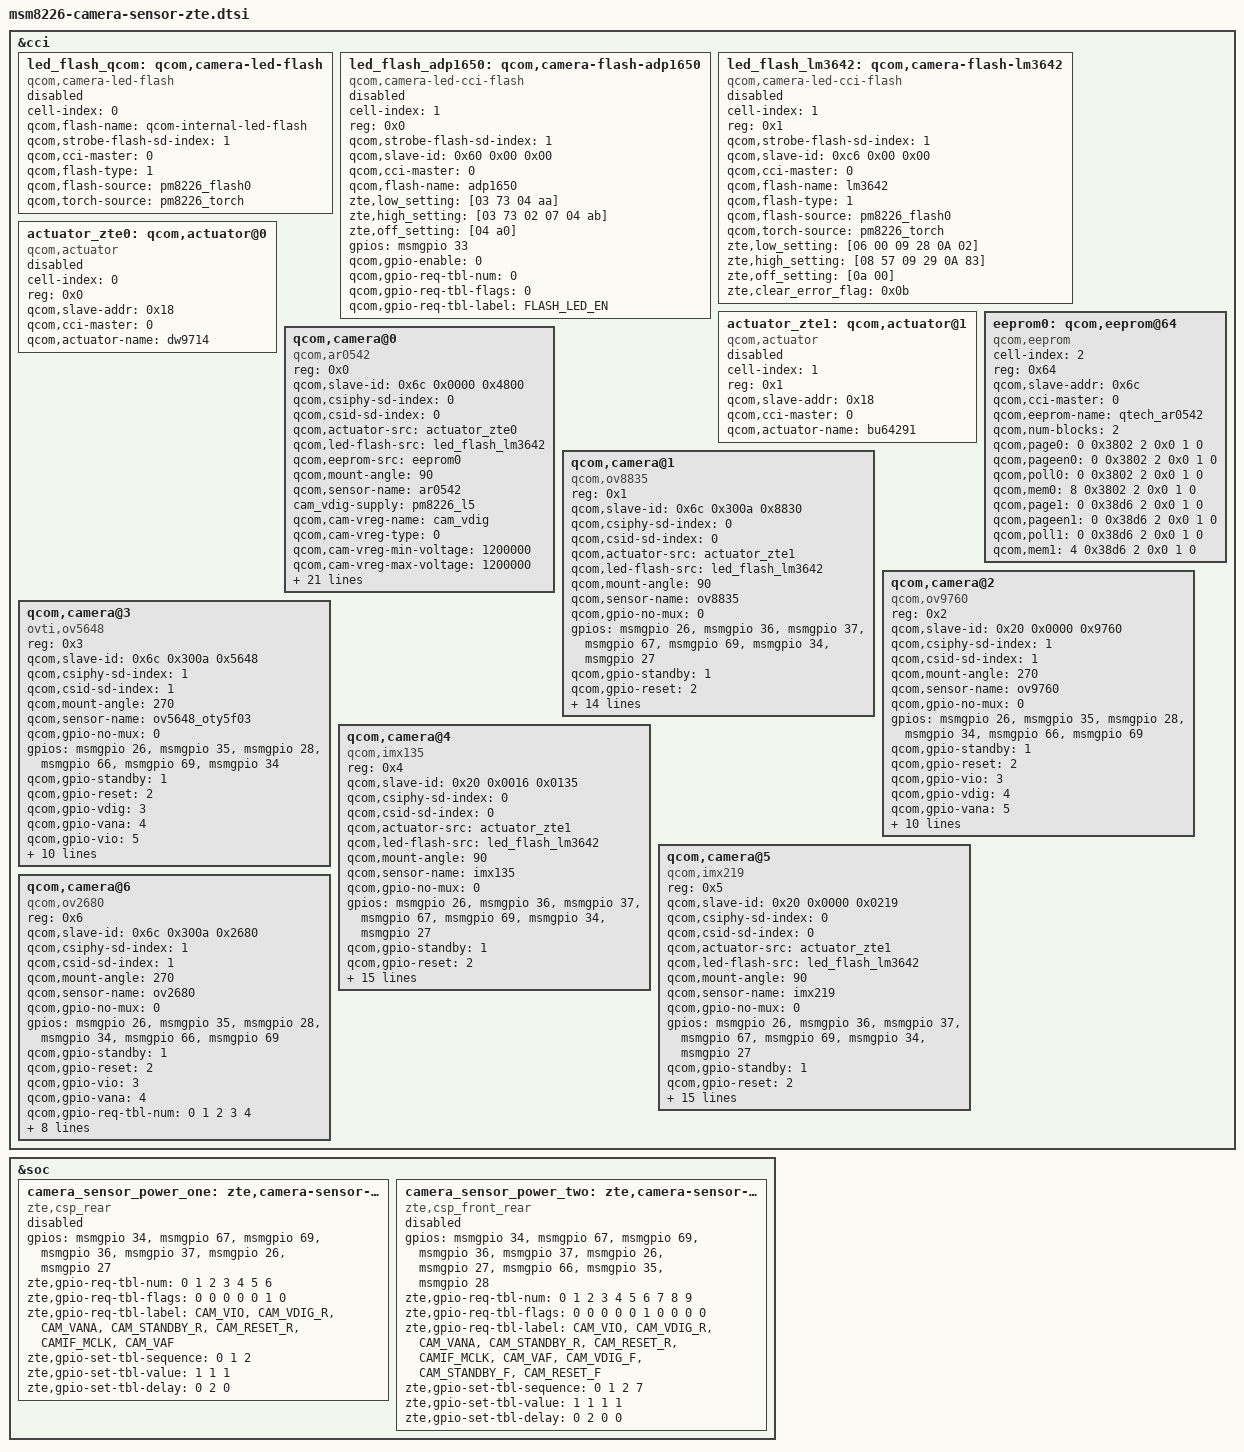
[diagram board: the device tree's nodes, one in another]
/*
 * Copyright (c) 2013, The Linux Foundation. All rights reserved.
 *
 * This program is free software; you can redistribute it and/or modify
 * it under the terms of the GNU General Public License version 2 and
 * only version 2 as published by the Free Software Foundation.
 *
 * This program is distributed in the hope that it will be useful,
 * but WITHOUT ANY WARRANTY; without even the implied warranty of
 * MERCHANTABILITY or FITNESS FOR A PARTICULAR PURPOSE.  See the
 * GNU General Public License for more details.
 */
	
&cci {

	/*
	 * Support for qcom internal flash
	 */
	led_flash_qcom: qcom,camera-led-flash {
		cell-index = <0>;
		qcom,flash-name = "qcom-internal-led-flash";
		qcom,strobe-flash-sd-index=<1>;
		compatible = "qcom,camera-led-flash";
		qcom,cci-master = <0>;
		qcom,flash-type = <1>;
		qcom,flash-source = <&pm8226_flash0>;
		qcom,torch-source = <&pm8226_torch>;
		status = "disabled";
	};

	
	/*
	 * Support for AD adp1650
	 */
	led_flash_adp1650:qcom,camera-flash-adp1650 {
		cell-index = <1>;
		reg = <0x0>;
		qcom,strobe-flash-sd-index=<1>;
		qcom,slave-id = <0x60 0x00 0x00>;
		compatible = "qcom,camera-led-cci-flash";
		qcom,cci-master = <0>;
		qcom,flash-name = "adp1650";
		zte,low_setting = [03  73  //torch current 100mA flash current 1000mA
					      04  aa];
		zte,high_setting = [03 73 //torch current 100mA flash current 1000mA
						02 07 //800ms
						04 ab];
		zte,off_setting = [04 a0];
		
		gpios = <&msmgpio 33 0>;
		qcom,gpio-enable = <0>;
		qcom,gpio-req-tbl-num = <0>;

		/* 0: output gpio, 1: input gpio */
		qcom,gpio-req-tbl-flags = <0>;

		qcom,gpio-req-tbl-label = "FLASH_LED_EN";

		status = "disabled";
	};

	/*
	 * Support for TI lm3642
	 */
	led_flash_lm3642: qcom,camera-flash-lm3642 {
		cell-index = <1>;
		reg = <0x1>;
		qcom,strobe-flash-sd-index=<1>;
		qcom,slave-id = <0xc6 0x00 0x00>;
		compatible = "qcom,camera-led-cci-flash";
		qcom,cci-master = <0>;
		qcom,flash-name = "lm3642";
		qcom,flash-type = <1>;
		qcom,flash-source = <&pm8226_flash0>;
		qcom,torch-source = <&pm8226_torch>;
		zte,low_setting = [06  00 // torch time, ramp-up time 16ms, ramp-down time 16ms
	 				      09  28   // current control, torch current 140.63mA, flash current 843.75mA
	 				      0A  02];  // enable register, torch mode, strobe pin disabled
		zte,high_setting = [08 57  // flash time, ramp time 1.024ms, time-out time 800ms
	 					09 29   // current control, torch current 140.63mA, flash current 937.5mA
	 					0A 83];  // enable register, flash mode, strobe pin disabled
		zte,off_setting = [0a 00];
		zte,clear_error_flag = <0x0b>;
		status = "disabled";
	};
	
	/*
	 * Support for Dongwoon dw9714
	 */
	actuator_zte0: qcom,actuator@0 {
		cell-index = <0>;
		reg = <0x0>;
		qcom,slave-addr = <0x18>;
		compatible = "qcom,actuator";
		qcom,cci-master = <0>;
		qcom,actuator-name = "dw9714";
		status = "disabled";
	};

	/*
	 * Support for Rohm bu64291
	 */
	actuator_zte1: qcom,actuator@1 {
		cell-index = <1>;
		reg = <0x1>;
		qcom,slave-addr = <0x18>;
		compatible = "qcom,actuator";
		qcom,cci-master = <0>;
		qcom,actuator-name = "bu64291";
		status = "disabled";
	};
	
	eeprom0: qcom,eeprom@64 {
	compatible = "qcom,eeprom";
	cell-index = <2>;
	reg = <0x64>;
	qcom,slave-addr = <0x6c>;
	qcom,cci-master = <0>;
	qcom,eeprom-name = "qtech_ar0542";
	qcom,num-blocks = <2>;

	qcom,page0   = <0 0x3802 2 0x0 1 0>;
	qcom,pageen0 = <0 0x3802 2 0x0 1 0>;
	qcom,poll0   = <0 0x3802 2 0x0 1 0>;
	qcom,mem0    = <8 0x3802 2 0x0 1 0>;

	qcom,page1   = <0 0x38d6 2 0x0 1 0>;
	qcom,pageen1 = <0 0x38d6 2 0x0 1 0>;
	qcom,poll1  = <0 0x38d6 2 0x0 1 0>;
	qcom,mem1    = <4 0x38d6 2 0x0 1 0>;
	};
	
	qcom,camera@0 {
		compatible = "qcom,ar0542";
		reg = <0x0>;
		qcom,slave-id = <0x6c 0x0000 0x4800>;
		qcom,csiphy-sd-index = <0>;
		qcom,csid-sd-index = <0>;
		qcom,actuator-src = <&actuator_zte0>;
		qcom,led-flash-src = <&led_flash_lm3642>;
		qcom,eeprom-src = <&eeprom0>;
		qcom,mount-angle = <90>;
		qcom,sensor-name = "ar0542";
		cam_vdig-supply = <&pm8226_l5>;
		qcom,cam-vreg-name = "cam_vdig";
		qcom,cam-vreg-type = <0>;
		qcom,cam-vreg-min-voltage = <1200000>;
		qcom,cam-vreg-max-voltage = <1200000>;
		qcom,cam-vreg-op-mode = <200000>;
		qcom,gpio-no-mux = <0>;
		gpios = <&msmgpio 26 0>,
			<&msmgpio 36 0>,
			<&msmgpio 37 0>,
			<&msmgpio 67 0>,
			<&msmgpio 69 0>,
			<&msmgpio 34 0>,
			<&msmgpio 27 0>;
		qcom,gpio-standby = <1>;
		qcom,gpio-reset = <2>;
		qcom,gpio-vdig = <3>;
		qcom,gpio-vana = <4>;
		qcom,gpio-vio = <5>;
		qcom,gpio-vaf = <6>;
		qcom,gpio-req-tbl-num = <0 1 2 3 4 5 6>;
		qcom,gpio-req-tbl-flags = <1 0 0 0 0 0 0>;
		qcom,gpio-req-tbl-label = "CAMIF_MCLK",
			"CAM_STANDBY",
			"CAM_RESET1",
			"CAM_VDIG",
			"CAM_VANA",
			"CAM_VIO",
			"CAM_VAF";
		qcom,csi-lane-assign = <0x4320>;
		qcom,csi-lane-mask = <0x7>;
		qcom,sensor-position = <0>;
		qcom,sensor-mode = <1>;
		qcom,cci-master = <0>;
		status = "ok";
	};

	qcom,camera@1 {
		compatible = "qcom,ov8835";
		reg = <0x1>;
		qcom,slave-id = <0x6c 0x300a 0x8830>;
		qcom,csiphy-sd-index = <0>;
		qcom,csid-sd-index = <0>;
		qcom,actuator-src = <&actuator_zte1>;
		qcom,led-flash-src = <&led_flash_lm3642>;
		qcom,mount-angle = <90>;
		qcom,sensor-name = "ov8835";
		qcom,gpio-no-mux = <0>;
		gpios = <&msmgpio 26 0>,
			<&msmgpio 36 0>,
			<&msmgpio 37 0>,
			<&msmgpio 67 0>,
			<&msmgpio 69 0>,
			<&msmgpio 34 0>,
			<&msmgpio 27 0>;
		qcom,gpio-standby = <1>;
		qcom,gpio-reset = <2>;
		qcom,gpio-vdig = <3>;
		qcom,gpio-vana = <4>;
		qcom,gpio-vio = <5>;
		qcom,gpio-vaf = <6>;
		qcom,gpio-req-tbl-num = <0 1 2 3 4 5 6>;
		qcom,gpio-req-tbl-flags = <1 0 0 0 0 0 0>;
		qcom,gpio-req-tbl-label = "CAMIF_MCLK",
			"CAM_STANDBY",
			"CAM_RESET1",
			"CAM_VDIG",
			"CAM_VANA",
			"CAM_VIO",
			"CAM_VAF";
		qcom,csi-lane-assign = <0x4320>;
		qcom,csi-lane-mask = <0x1f>;
		qcom,sensor-position = <0>;
		qcom,sensor-mode = <1>;
		qcom,cci-master = <0>;
		status = "ok";
	};

	qcom,camera@2 {
		compatible = "qcom,ov9760";
		reg = <0x2>;
		qcom,slave-id = <0x20 0x0000 0x9760>;
		qcom,csiphy-sd-index = <1>;
		qcom,csid-sd-index = <1>;
		qcom,mount-angle = <270>;
		qcom,sensor-name = "ov9760";
		qcom,gpio-no-mux = <0>;
		gpios = <&msmgpio 26 0>,
			<&msmgpio 35 0>,
			<&msmgpio 28 0>,
			<&msmgpio 34 0>,
			<&msmgpio 66 0>,
			<&msmgpio 69 0>;
		qcom,gpio-standby = <1>;
		qcom,gpio-reset = <2>;
		qcom,gpio-vio = <3>;
		qcom,gpio-vdig = <4>;
		qcom,gpio-vana = <5>;
		qcom,gpio-req-tbl-num = <0 1 2 3 4 5>;
		qcom,gpio-req-tbl-flags = <1 0 0 0 0 0>;
		qcom,gpio-req-tbl-label = "CAMIF_MCLK",
			"CAM_STANDBY",
			"CAM_RESET",
			"CAM_VIO",
			"CAM_VDIG",
			"CAM_VANA";
		qcom,csi-lane-assign = <0x4320>;
		qcom,csi-lane-mask = <0x3>;
		qcom,sensor-position = <1>;
		qcom,sensor-mode = <1>;
		qcom,cci-master = <0>;
		status = "ok";
	};
	qcom,camera@3 {
		compatible = "ovti,ov5648";
		reg = <0x3>;
		qcom,slave-id = <0x6c 0x300a 0x5648>;
		qcom,csiphy-sd-index = <1>;
		qcom,csid-sd-index = <1>;
		qcom,mount-angle = <270>;
		qcom,sensor-name = "ov5648_oty5f03";
		qcom,gpio-no-mux = <0>;
		gpios = <&msmgpio 26 0>,
			<&msmgpio 35 0>,
			<&msmgpio 28 0>,
			<&msmgpio 66 0>,
			<&msmgpio 69 0>,
			<&msmgpio 34 0>;
		qcom,gpio-standby = <1>;
		qcom,gpio-reset = <2>;
		qcom,gpio-vdig = <3>;
		qcom,gpio-vana = <4>;
		qcom,gpio-vio = <5>;
		qcom,gpio-req-tbl-num = <0 1 2 3 4 5>;
		qcom,gpio-req-tbl-flags = <1 0 0 0 0 0>;
		qcom,gpio-req-tbl-label = "CAMIF_MCLK",
			"CAM_STANDBY",
			"CAM_RESET1",
			"CAM_VDIG",
			"CAM_VANA",
			"CAM_VIO";
		qcom,csi-lane-assign = <0x4320>;
		qcom,csi-lane-mask = <0x3>;
		qcom,sensor-position = <1>;
		qcom,sensor-mode = <1>;
		qcom,cci-master = <0>;
		status = "ok";
	};

   	 qcom,camera@4 {
		compatible = "qcom,imx135";
		reg = <0x4>;
		qcom,slave-id = <0x20 0x0016 0x0135>;
		qcom,csiphy-sd-index = <0>;
		qcom,csid-sd-index = <0>;
		qcom,actuator-src = <&actuator_zte1>;
		qcom,led-flash-src = <&led_flash_lm3642>;
		qcom,mount-angle = <90>;
		qcom,sensor-name = "imx135";
		qcom,gpio-no-mux = <0>;
		gpios = <&msmgpio 26 0>,
			<&msmgpio 36 0>,
			<&msmgpio 37 0>,
			<&msmgpio 67 0>,
			<&msmgpio 69 0>,
			<&msmgpio 34 0>,
			<&msmgpio 27 0>;
		qcom,gpio-standby = <1>;
		qcom,gpio-reset = <2>;
		qcom,gpio-vdig = <3>;
		qcom,gpio-vana = <4>;
		qcom,gpio-vio = <5>;
		qcom,gpio-vaf = <6>;
		qcom,gpio-req-tbl-num = <0 1 2 3 4 5 6>;
		qcom,gpio-req-tbl-flags = <1 0 0 0 0 0 0>;
		qcom,gpio-req-tbl-label = "CAMIF_MCLK",
			"CAM_STANDBY",
			"CAM_RESET1",
			"CAM_VDIG",
			"CAM_VANA",
			"CAM_VIO",
			"CAM_VAF";
		qcom,csi-lane-assign = <0x4320>;
		qcom,csi-lane-mask = <0x1f>;
		qcom,sensor-position = <0>;
		qcom,sensor-mode = <0>;
		qcom,sensor-type = <0>;
		qcom,cci-master = <0>;
		status = "ok";
	};

   	 qcom,camera@5 {
		compatible = "qcom,imx219";
		reg = <0x5>;
		qcom,slave-id = <0x20 0x0000 0x0219>;
		qcom,csiphy-sd-index = <0>;
		qcom,csid-sd-index = <0>;
		qcom,actuator-src = <&actuator_zte1>;
		qcom,led-flash-src = <&led_flash_lm3642>;
		qcom,mount-angle = <90>;
		qcom,sensor-name = "imx219";
		qcom,gpio-no-mux = <0>;
		gpios = <&msmgpio 26 0>,
			<&msmgpio 36 0>,
			<&msmgpio 37 0>,
			<&msmgpio 67 0>,
			<&msmgpio 69 0>,
			<&msmgpio 34 0>,
			<&msmgpio 27 0>;
		qcom,gpio-standby = <1>;
		qcom,gpio-reset = <2>;
		qcom,gpio-vdig = <3>;
		qcom,gpio-vana = <4>;
		qcom,gpio-vio = <5>;
		qcom,gpio-vaf = <6>;
		qcom,gpio-req-tbl-num = <0 1 2 3 4 5 6>;
		qcom,gpio-req-tbl-flags = <1 0 0 0 0 0 0>;
		qcom,gpio-req-tbl-label = "CAMIF_MCLK",
			"CAM_STANDBY",
			"CAM_RESET1",
			"CAM_VDIG",
			"CAM_VANA",
			"CAM_VIO",
			"CAM_VAF";
		qcom,csi-lane-assign = <0x4320>;
		qcom,csi-lane-mask = <0x1f>;
		qcom,sensor-position = <0>;
		qcom,sensor-mode = <0>;
		qcom,sensor-type = <0>;
		qcom,cci-master = <0>;
		status = "ok";
	};

	qcom,camera@6 {
		compatible = "qcom,ov2680";
		reg = <0x6>;
		qcom,slave-id = <0x6c 0x300a 0x2680>;
		qcom,csiphy-sd-index = <1>;
		qcom,csid-sd-index = <1>;
		qcom,mount-angle = <270>;
		qcom,sensor-name = "ov2680";
		qcom,gpio-no-mux = <0>;
		gpios = <&msmgpio 26 0>,
			<&msmgpio 35 0>,
			<&msmgpio 28 0>,
			<&msmgpio 34 0>,
			<&msmgpio 66 0>,
			<&msmgpio 69 0>;
		qcom,gpio-standby = <1>;
		qcom,gpio-reset = <2>;
		qcom,gpio-vio = <3>;
		qcom,gpio-vana = <4>;
		qcom,gpio-req-tbl-num = <0 1 2 3 4>;
		qcom,gpio-req-tbl-flags = <1 0 0 0 0>;
		qcom,gpio-req-tbl-label = "CAMIF_MCLK",
			"CAM_STANDBY",
			"CAM_RESET",
			"CAM_VIO",
			"CAM_VANA";
		qcom,csi-lane-assign = <0x4320>;
		qcom,csi-lane-mask = <0x3>;
		qcom,sensor-position = <1>;
		qcom,sensor-mode = <1>;
		qcom,cci-master = <0>;
		status = "ok";
	};	 

};
&soc {
	//there is only rear camera
	camera_sensor_power_one:zte,camera-sensor-power_one {
		compatible = "zte,csp_rear";
		gpios = 
			     <&msmgpio 34 0>,  //CAM_VIO            0
			     <&msmgpio 67 0>,  //CAM_VDIG_R       1
			     <&msmgpio 69 0>,  //CAM_VANA          2
			   
			     
			     <&msmgpio 36 0>,  //CAM_STANDBY_R  3
			     <&msmgpio 37 0>,  //CAM_RESET_R      4
			     
			     <&msmgpio 26 0>,  //CAMIF_MCLK        5
			     
			     <&msmgpio 27 0>; //CAM_VAF             6	
			     
		zte,gpio-req-tbl-num = <0 1 2 3 4 5 6>;
		zte,gpio-req-tbl-flags = <0 0 0 0 0 1 0>; // 0:output low  1: input  2:output hight
		zte,gpio-req-tbl-label = "CAM_VIO",
							   "CAM_VDIG_R",
							   "CAM_VANA",
							   
							   "CAM_STANDBY_R",
							   "CAM_RESET_R",	
							   
							   "CAMIF_MCLK",
							   
							   "CAM_VAF";
							   
		zte,gpio-set-tbl-sequence = <0 1 2>; //power up sequence
		zte,gpio-set-tbl-value = <1 1 1>;      //power up ,gpio output value
		zte,gpio-set-tbl-delay = <0 2 0>;      //power up ,the delay after gpio output
		status = "disabled";
	};

	//there is front and rear camera	
	camera_sensor_power_two:zte,camera-sensor-power_two {
		compatible = "zte,csp_front_rear";
		gpios = 
			     <&msmgpio 34 0>,  //CAM_VIO            0
			     <&msmgpio 67 0>,  //CAM_VDIG_R       1
			     <&msmgpio 69 0>,  //CAM_VANA          2			   
			     
			     <&msmgpio 36 0>,  //CAM_STANDBY_R  3
			     <&msmgpio 37 0>,  //CAM_RESET_R      4
			     
			     <&msmgpio 26 0>,  //CAMIF_MCLK        5
			     
			     <&msmgpio 27 0>,  //CAM_VAF             6	
		
			      <&msmgpio 66 0>,  //CAM_VDIG_F       7
			      <&msmgpio 35 0>,  //CAM_STANDBY_F  8	
			     <&msmgpio 28 0>;  //CAM_RESET_F       9
			     
		zte,gpio-req-tbl-num = <0 1 2 3 4 5 6 7 8 9>;
		zte,gpio-req-tbl-flags = <0 0 0 0 0 1 0 0 0 0>; // 0:output low  1: input  2:output hight
		zte,gpio-req-tbl-label = "CAM_VIO",
							   "CAM_VDIG_R",
							   "CAM_VANA",
							   
							   "CAM_STANDBY_R",
							   "CAM_RESET_R",	
							   
							   "CAMIF_MCLK",
							   
							   "CAM_VAF",
							   
							   "CAM_VDIG_F",
							   "CAM_STANDBY_F",
							   "CAM_RESET_F";
		zte,gpio-set-tbl-sequence = <0 1 2 7>; //power up sequence
		zte,gpio-set-tbl-value = <1 1 1 1>;      //power up ,gpio output value
		zte,gpio-set-tbl-delay = <0 2 0 0>;      //power up ,the delay after gpio output
		status = "disabled";
	};
};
